# STM32G070 register map
File version: 1.4
CPU: CM0 r0p1, little endian, MPU, no FPU, 2 interrupt priority bits
Registers are 32-bit, read-write, reset 0x0 unless marked. A register's access mark holds for its fields unless they carry their own. Offsets are from the block's base; [hi:lo] are bit positions; {n}, {i} and the like mark numbered series; 'fields as' and 'values as' point back to an identical list.

## EXTI — External interrupt/event controller
Base 0x40021800
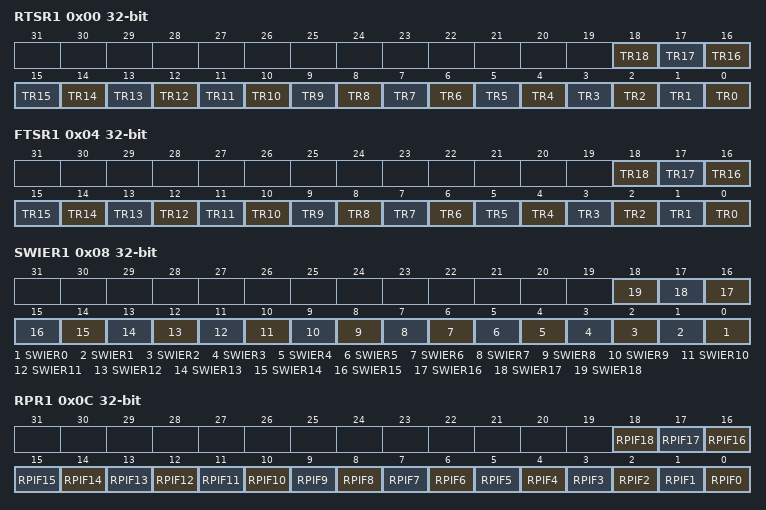
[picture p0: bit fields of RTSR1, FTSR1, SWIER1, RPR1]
0x00 RTSR1 — EXTI rising trigger selection register
  [all] fields
    0=Disabled (Rising edge trigger is disabled); 1=Enabled (Rising edge trigger is enabled)
  [n] TR{n} (n=0..18) — Rising trigger event configuration bit of Configurable Event input
0x04 FTSR1 — EXTI falling trigger selection register
  [all] fields
    0=Disabled (Falling edge trigger is disabled); 1=Enabled (Falling edge trigger is enabled)
  [n] TR{n} (n=0..18) — Rising trigger event configuration bit of Configurable Event input
0x08 SWIER1 — EXTI software interrupt event register
  [all] fields
    on write: 1=Pend (Generates an interrupt request)
  [n] SWIER{n} (n=0..18) — Rising trigger event configuration bit of Configurable Event input
0x0C RPR1 — EXTI rising edge pending register
  [all] fields
    on read: 0=NotPending (No trigger request occurred); 1=Pending (Selected trigger request occurred) | on write: 1=Clears pending bit
  [n] RPIF{n} (n=6..18) — configurable event inputs x rising edge Pending bit.
  [5] RPIF5 — configurable event inputs x rising edge Pending bit
  [n] RPIF{n} (n=0..4) — configurable event inputs x rising edge Pending bit.
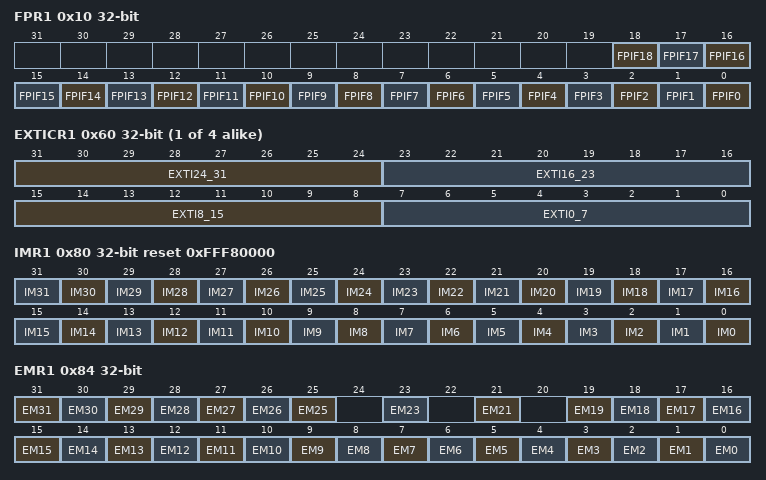
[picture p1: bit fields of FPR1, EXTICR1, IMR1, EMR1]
0x10 FPR1 — EXTI falling edge pending register
  [all] fields
    values as the fields of RPR1
  [n] FPIF{n} (n=0..18) — configurable event inputs x falling edge pending bit.
{0x5C+4i} EXTICR{i} (i=1..4) — EXTI external interrupt selection register
  [all] fields
    0=PA (GPIO port A selected); 1=PB (GPIO port B selected); 2=PC (GPIO port C selected); 3=PD (GPIO port D selected); 5=PF (GPIO port F selected)
  [31:24] EXTI24_31 — GPIO port selection
  [23:16] EXTI16_23 — GPIO port selection
  [15:8] EXTI8_15 — GPIO port selection
  [7:0] EXTI0_7 — GPIO port selection
0x80 IMR1 reset 0xFFF80000 — EXTI CPU wakeup with interrupt mask register
  [all] fields
    0=Masked (Interrupt request line is masked); 1=Unmasked (Interrupt request line is unmasked)
  [n] IM{n} (n=0..31) — CPU wakeup with interrupt mask on event input
0x84 EMR1 (alternate view of IMR1) — EXTI CPU wakeup with event mask register
  [all] fields
    values as the fields of IMR1
  [n] EM{n} (n=25..31) — CPU wakeup with event mask on event input
  [23] EM23 — CPU wakeup with event mask on event input
  [21] EM21 — CPU wakeup with event mask on event input
  [n] EM{n} (n=0..19) — CPU wakeup with event mask on event input
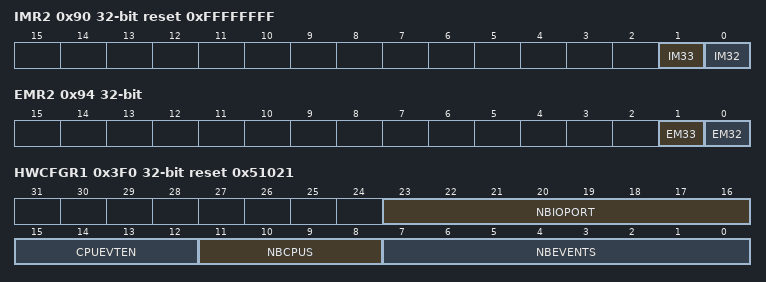
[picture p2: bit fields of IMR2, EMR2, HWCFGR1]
0x90 IMR2 reset 0xFFFFFFFF — EXTI CPU wakeup with interrupt mask register
  [1] IM33 — CPU wakeup with interrupt mask on event input
    values as the fields of IMR1
  [0] IM32 — CPU wakeup with interrupt mask on event input
    values as the fields of IMR1
0x94 EMR2 — EXTI CPU wakeup with event mask register
  [1] EM33 — CPU wakeup with event mask on event input
    values as the fields of IMR1
  [0] EM32 — CPU wakeup with event mask on event input
    values as the fields of IMR1
0x3D8 HWCFGR7 — Hardware configuration registers
  [31:0] CPUEVENT — HW configuration CPU event generation
0x3DC HWCFGR6 reset 0x3 — Hardware configuration registers
  [31:0] CPUEVENT — HW configuration CPU event generation
0x3E0 HWCFGR5 reset 0xFEAFFFFF — Hardware configuration registers
  [31:0] CPUEVENT — HW configuration CPU event generation
0x3E4 HWCFGR4 — Hardware configuration registers
  [31:0] EVENT_TRG — HW configuration event trigger type
0x3E8 HWCFGR3 — Hardware configuration registers
  [31:0] EVENT_TRG — HW configuration event trigger type
0x3EC HWCFGR2 reset 0x7FFFF — Hardware configuration registers
  [31:0] EVENT_TRG — HW configuration event trigger type
0x3F0 HWCFGR1 ro reset 0x51021 — Hardware configuration registers
  [23:16] NBIOPORT — HW configuration of number of IO ports
  [15:12] CPUEVTEN — HW configuration of CPU event output enable
  [11:8] NBCPUS — configuration number of CPUs
  [7:0] NBEVENTS — configuration number of event
